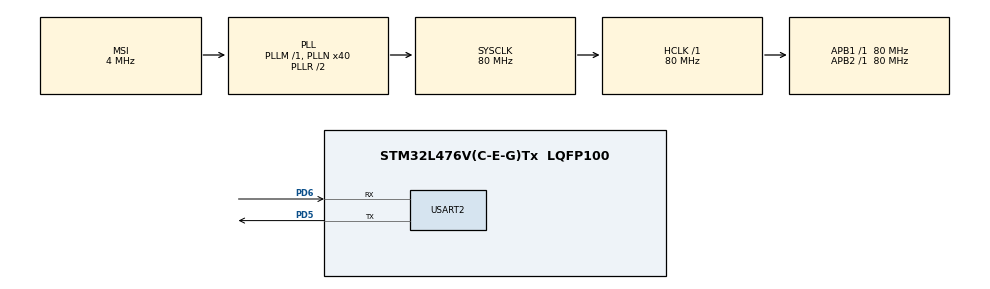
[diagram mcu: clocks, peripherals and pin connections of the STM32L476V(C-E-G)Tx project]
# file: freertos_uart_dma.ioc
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Dma.Request0=USART2_RX
Dma.Request1=USART2_TX
Dma.USART2_RX.0.Direction=DMA_PERIPH_TO_MEMORY
Dma.USART2_RX.0.Instance=DMA1_Channel6
Dma.USART2_RX.0.MemDataAlignment=DMA_MDATAALIGN_BYTE
Dma.USART2_RX.0.MemInc=DMA_MINC_ENABLE
Dma.USART2_RX.0.Mode=DMA_CIRCULAR
Dma.USART2_RX.0.PeriphDataAlignment=DMA_PDATAALIGN_BYTE
Dma.USART2_RX.0.PeriphInc=DMA_PINC_DISABLE
Dma.USART2_RX.0.Priority=DMA_PRIORITY_LOW
Dma.USART2_TX.1.Direction=DMA_MEMORY_TO_PERIPH
Dma.USART2_TX.1.Instance=DMA1_Channel7
Dma.USART2_TX.1.MemDataAlignment=DMA_MDATAALIGN_BYTE
Dma.USART2_TX.1.MemInc=DMA_MINC_ENABLE
Dma.USART2_TX.1.Mode=DMA_NORMAL
Dma.USART2_TX.1.PeriphDataAlignment=DMA_PDATAALIGN_BYTE
Dma.USART2_TX.1.PeriphInc=DMA_PINC_DISABLE
Dma.USART2_TX.1.Priority=DMA_PRIORITY_LOW
FREERTOS.Tasks01=defaultTask,0,128,StartDefaultTask,Default,NULL
Mcu.Family=STM32L4
Mcu.Name=STM32L476V(C-E-G)Tx
Mcu.Package=LQFP100
NVIC.DMA1_Channel6_IRQn=true\:5\:0\:false\:false\:true\:true\:false\:true
NVIC.DMA1_Channel7_IRQn=true\:5\:0\:false\:false\:true\:true\:false\:true
NVIC.PriorityGroup=NVIC_PRIORITYGROUP_4
NVIC.TIM6_DAC_IRQn=true\:0\:0\:false\:false\:true\:false\:false\:true
NVIC.TimeBase=TIM6_DAC_IRQn
NVIC.TimeBaseIP=TIM6
PD5.Mode=Asynchronous
PD5.Signal=USART2_TX
PD6.Mode=Asynchronous
PD6.Signal=USART2_RX
ProjectManager.HeapSize=0x200
ProjectManager.StackSize=0x400
ProjectManager.TargetToolchain=EWARM V8
RCC.AHBFreq_Value=80000000
RCC.APB1Freq_Value=80000000
RCC.APB1TimFreq_Value=80000000
RCC.APB2Freq_Value=80000000
RCC.APB2TimFreq_Value=80000000
RCC.CortexFreq_Value=80000000
RCC.HCLKFreq_Value=80000000
RCC.HSE_VALUE=8000000
RCC.HSI_VALUE=16000000
RCC.LSE_VALUE=32768
RCC.MSI_VALUE=4000000
RCC.PLLN=40
RCC.SYSCLKFreq_VALUE=80000000
RCC.SYSCLKSource=RCC_SYSCLKSOURCE_PLLCLK
RCC.VCOOutputFreq_Value=160000000
USART2.VirtualMode-Asynchronous=VM_ASYNC
VP_FREERTOS_VS_CMSIS_V1.Mode=CMSIS_V1
VP_SYS_VS_tim6.Mode=TIM6
board=custom

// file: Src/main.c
/* USER CODE BEGIN Header */
/**
  ******************************************************************************
  * @file           : main.c
  * @brief          : Main program body
  ******************************************************************************
  * @attention
  *
  * <h2><center>&copy; Copyright (c) 2019 STMicroelectronics.
  * All rights reserved.</center></h2>
  *
  * This software component is licensed by ST under BSD 3-Clause license,
  * the "License"; You may not use this file except in compliance with the
  * License. You may obtain a copy of the License at:
  *                        opensource.org/licenses/BSD-3-Clause
  *
  ******************************************************************************
  */
/* USER CODE END Header */

#include "main.h"
#include "cmsis_os.h"

/* USER CODE BEGIN PD */
#define RX_BUFFER_SIZE    32
#define QUEUE_SIZE        RX_BUFFER_SIZE
#define RX_ONE_BYTE       1
#define START_CMD_SIZE    6
#define STOP_CMD_SIZE     5

#define START_CMD         "start\n"
#define STOP_CMD          "stop\n"
#define LF                '\n'
#define CR                '\r'
#define CR_LF             "\r\n"
/* USER CODE END PD */

UART_HandleTypeDef huart2;
DMA_HandleTypeDef hdma_usart2_rx;
DMA_HandleTypeDef hdma_usart2_tx;

osThreadId defaultTaskHandle;
/* USER CODE BEGIN PV */
uint8_t uRxByte;
uint8_t aRxBuffer[RX_BUFFER_SIZE];
QueueHandle_t xQueue;
/* USER CODE END PV */

void SystemClock_Config(void);
static void MX_GPIO_Init(void);
static void MX_DMA_Init(void);
static void MX_USART2_UART_Init(void);

/* USER CODE BEGIN PFP */
static void vTask1(void *pvParameters);
/* USER CODE END PFP */

int main(void)
{

  /* MCU Configuration--------------------------------------------------------*/

  /* Reset of all peripherals, Initializes the Flash interface and the Systick. */
  HAL_Init();

  /* Configure the system clock */
  SystemClock_Config();

  /* Initialize all configured peripherals */
  MX_GPIO_Init();
  MX_DMA_Init();
  MX_USART2_UART_Init();
  /* USER CODE BEGIN 2 */
  HAL_UART_Receive_DMA(&huart2, aRxBuffer, RX_BUFFER_SIZE);
  /* USER CODE END 2 */

  /* USER CODE BEGIN RTOS_QUEUES */
  xQueue = xQueueCreate(QUEUE_SIZE, sizeof(uint8_t));
  if (xQueue == NULL)
  {
    Error_Handler();
  }
  /* USER CODE END RTOS_QUEUES */

  /* USER CODE BEGIN RTOS_THREADS */
  xTaskCreate(vTask1, "Task 1", 128, NULL, osPriorityHigh, NULL);
  /* USER CODE END RTOS_THREADS */

  /* Start scheduler */
  vTaskStartScheduler();

  /* We should never get here as control is now taken by the scheduler */

  /* Infinite loop */
  /* USER CODE BEGIN WHILE */
  while (1)
  {
    printf("Running in main\n");
    HAL_Delay(1000);
    /* USER CODE END WHILE */

  }
}

void SystemClock_Config(void)
{
  RCC_OscInitTypeDef RCC_OscInitStruct = {0};
  RCC_ClkInitTypeDef RCC_ClkInitStruct = {0};
  RCC_PeriphCLKInitTypeDef PeriphClkInit = {0};

  /** Initializes the CPU, AHB and APB busses clocks
  */
  RCC_OscInitStruct.OscillatorType = RCC_OSCILLATORTYPE_MSI;
  RCC_OscInitStruct.MSIState = RCC_MSI_ON;
  RCC_OscInitStruct.MSICalibrationValue = 0;
  RCC_OscInitStruct.MSIClockRange = RCC_MSIRANGE_6;
  RCC_OscInitStruct.PLL.PLLState = RCC_PLL_ON;
  RCC_OscInitStruct.PLL.PLLSource = RCC_PLLSOURCE_MSI;
  RCC_OscInitStruct.PLL.PLLM = 1;
  RCC_OscInitStruct.PLL.PLLN = 40;
  RCC_OscInitStruct.PLL.PLLP = RCC_PLLP_DIV7;
  RCC_OscInitStruct.PLL.PLLQ = RCC_PLLQ_DIV2;
  RCC_OscInitStruct.PLL.PLLR = RCC_PLLR_DIV2;
  if (HAL_RCC_OscConfig(&RCC_OscInitStruct) != HAL_OK)
  {
    Error_Handler();
  }
  /** Initializes the CPU, AHB and APB busses clocks
  */
  RCC_ClkInitStruct.ClockType = RCC_CLOCKTYPE_HCLK|RCC_CLOCKTYPE_SYSCLK
                              |RCC_CLOCKTYPE_PCLK1|RCC_CLOCKTYPE_PCLK2;
  RCC_ClkInitStruct.SYSCLKSource = RCC_SYSCLKSOURCE_PLLCLK;
  RCC_ClkInitStruct.AHBCLKDivider = RCC_SYSCLK_DIV1;
  RCC_ClkInitStruct.APB1CLKDivider = RCC_HCLK_DIV1;
  RCC_ClkInitStruct.APB2CLKDivider = RCC_HCLK_DIV1;

  if (HAL_RCC_ClockConfig(&RCC_ClkInitStruct, FLASH_LATENCY_4) != HAL_OK)
  {
    Error_Handler();
  }
  PeriphClkInit.PeriphClockSelection = RCC_PERIPHCLK_USART2;
  PeriphClkInit.Usart2ClockSelection = RCC_USART2CLKSOURCE_PCLK1;
  if (HAL_RCCEx_PeriphCLKConfig(&PeriphClkInit) != HAL_OK)
  {
    Error_Handler();
  }
  /** Configure the main internal regulator output voltage
  */
  if (HAL_PWREx_ControlVoltageScaling(PWR_REGULATOR_VOLTAGE_SCALE1) != HAL_OK)
  {
    Error_Handler();
  }
}

static void MX_USART2_UART_Init(void)
{

  huart2.Instance = USART2;
  huart2.Init.BaudRate = 115200;
  huart2.Init.WordLength = UART_WORDLENGTH_8B;
  huart2.Init.StopBits = UART_STOPBITS_1;
  huart2.Init.Parity = UART_PARITY_NONE;
  huart2.Init.Mode = UART_MODE_TX_RX;
  huart2.Init.HwFlowCtl = UART_HWCONTROL_NONE;
  huart2.Init.OverSampling = UART_OVERSAMPLING_16;
  huart2.Init.OneBitSampling = UART_ONE_BIT_SAMPLE_DISABLE;
  huart2.AdvancedInit.AdvFeatureInit = UART_ADVFEATURE_NO_INIT;
  if (HAL_UART_Init(&huart2) != HAL_OK)
  {
    Error_Handler();
  }

}

static void MX_DMA_Init(void)
{

  /* DMA controller clock enable */
  __HAL_RCC_DMA1_CLK_ENABLE();

  /* DMA interrupt init */
  /* DMA1_Channel6_IRQn interrupt configuration */
  HAL_NVIC_SetPriority(DMA1_Channel6_IRQn, 5, 0);
  HAL_NVIC_EnableIRQ(DMA1_Channel6_IRQn);
  /* DMA1_Channel7_IRQn interrupt configuration */
  HAL_NVIC_SetPriority(DMA1_Channel7_IRQn, 5, 0);
  HAL_NVIC_EnableIRQ(DMA1_Channel7_IRQn);

}

static void MX_GPIO_Init(void)
{

  /* GPIO Ports Clock Enable */
  __HAL_RCC_GPIOD_CLK_ENABLE();

}

/* USER CODE BEGIN 4 */
void vTask1(void *pvParameters)
{
  const TickType_t xDelayInMs = pdMS_TO_TICKS(100);
  uint8_t byte;
  uint8_t index = 0;

  for(;;)
  {
    if(xQueueReceive(xQueue, &byte, 0))
    {
      aRxBuffer[index] = byte;
      if (byte == LF)
      {
        // printf("Should Echo Here\n");
        HAL_UART_Transmit_DMA(&huart2, aRxBuffer, index);
        memset(aRxBuffer, 0, RX_BUFFER_SIZE);
        index = 0;
      }
      index++;
    }
    vTaskDelay(xDelayInMs);
  }
}

void HAL_UART_RxHalfCpltCallback(UART_HandleTypeDef *huart)
{
  // printf("UART RX Half Callback\n");
}

void HAL_UART_RxCpltCallback(UART_HandleTypeDef *huart)
{
  // printf("UART RX Callback\n");
  if (huart->Instance == USART2)
  {
    if (xQueueSendFromISR(xQueue, aRxBuffer, NULL))
    {
      __NOP();
    }
    else
    {
      __NOP();
    }
  }
}

void HAL_UART_ErrorCallback(UART_HandleTypeDef *huart)
{
  printf("Error Callback\n");
}
/* USER CODE END 4 */

void HAL_TIM_PeriodElapsedCallback(TIM_HandleTypeDef *htim)
{
  if (htim->Instance == TIM6) {
    HAL_IncTick();
  }
}

void Error_Handler(void)
{
  /* USER CODE BEGIN Error_Handler_Debug */
  /* User can add his own implementation to report the HAL error return state */
  printf("Error Handler\n");
  while (1);
  /* USER CODE END Error_Handler_Debug */
}

/************************ (C) COPYRIGHT STMicroelectronics *****END OF FILE****/
